# MIMXRT685S_cm33 register map
Vendor: nxp.com; File version: 1.0
CPU: CM33 r2p0, little endian, MPU, FPU, VTOR, 3 interrupt priority bits
Registers are 32-bit, read-write, reset 0x0 unless marked. A register's access mark holds for its fields unless they carry their own. Offsets are from the block's base; [hi:lo] are bit positions; {n}, {i} and the like mark numbered series.

## USBHSD — LPC54S60x/LPC5460x USB1 High-speed Device Controller
Base 0x40144000
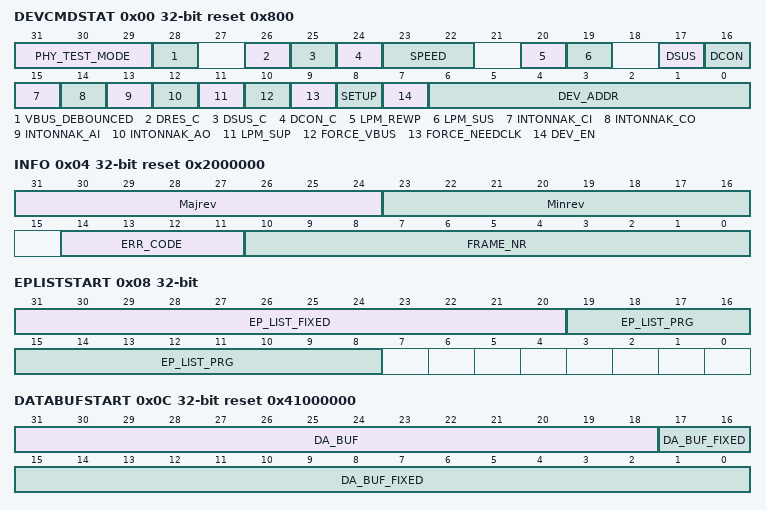
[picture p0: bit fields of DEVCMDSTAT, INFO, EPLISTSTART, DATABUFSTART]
0x00 DEVCMDSTAT reset 0x800 — USB Device Command/Status register
  [31:29] PHY_TEST_MODE — This field is written by firmware to put the PHY into a test mode as defined by the USB2.0 specification.
  [28] VBUS_DEBOUNCED ro — This bit indicates if VBUS is detected or not.
  [26] DRES_C — Device status - reset change.
  [25] DSUS_C — Device status - suspend change.
  [24] DCON_C — Device status - connect change.
  [23:22] SPEED ro — This field indicates the speed at which the device operates: 00b: reserved 01b: full-speed 10b: high-speed 11b: super-speed (reserved for future use).
  [20] LPM_REWP ro — LPM Remote Wake-up Enabled by USB host.
  [19] LPM_SUS — Device status - LPM Suspend.
  [17] DSUS — Device status - suspend.
  [16] DCON — Device status - connect.
  [15] INTONNAK_CI — Interrupt on NAK for control IN EP:.
  [14] INTONNAK_CO — Interrupt on NAK for control OUT EP:.
  [13] INTONNAK_AI — Interrupt on NAK for interrupt and bulk IN EP:.
  [12] INTONNAK_AO — Interrupt on NAK for interrupt and bulk OUT EP:.
  [11] LPM_SUP — LPM Supported:.
  [10] FORCE_VBUS — If this bit is set to 1, the VBUS voltage indicators from the PHY are overruled.
  [9] FORCE_NEEDCLK — Forces the NEEDCLK output to always be on:.
  [8] SETUP — SETUP token received.
  [7] DEV_EN — USB device enable.
  [6:0] DEV_ADDR — USB device address.
0x04 INFO ro reset 0x2000000 — USB Info register
  [31:24] Majrev — Major revision.
  [23:16] Minrev — Minor revision.
  [14:11] ERR_CODE — The error code which last occurred:.
  [10:0] FRAME_NR — Frame number.
0x08 EPLISTSTART — USB EP Command/Status List start address
  [31:20] EP_LIST_FIXED ro — Fixed portion of USB EP Command/Status List address.
  [19:8] EP_LIST_PRG — Programmable portion of the USB EP Command/Status List address.
0x0C DATABUFSTART reset 0x41000000 — USB Data buffer start address
  [31:18] DA_BUF — Programmable portion of the data buffer start address.
  [17:0] DA_BUF_FIXED ro — The fixed portion of the data buffer start address.
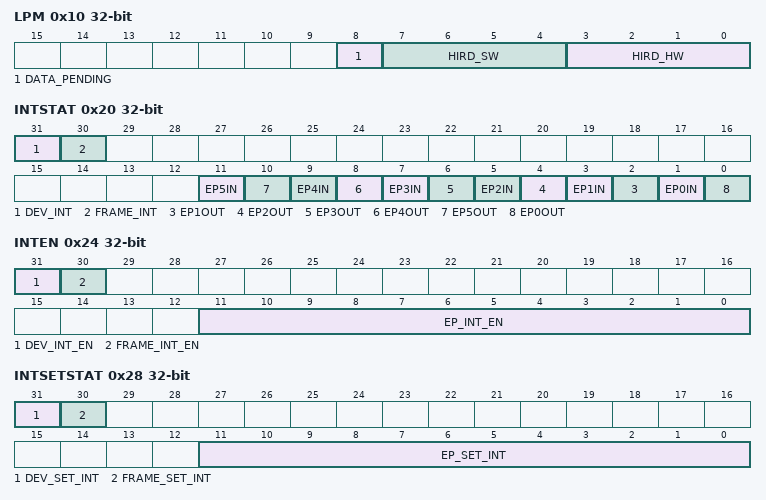
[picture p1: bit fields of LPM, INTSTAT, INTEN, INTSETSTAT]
0x10 LPM — USB Link Power Management register
  [8] DATA_PENDING — As long as this bit is set to one and LPM supported bit is set to one, HW will return a NYET handshake on every LPM token it receives.
  [7:4] HIRD_SW — Host Initiated Resume Duration - SW.
  [3:0] HIRD_HW ro — Host Initiated Resume Duration - HW.
0x14 EPSKIP — USB Endpoint skip
  [11:0] SKIP — Endpoint skip: Writing 1 to one of these bits, will indicate to HW that it must deactivate the buffer assigned to this endpoint and return control back to software.
0x18 EPINUSE — USB Endpoint Buffer in use
  [11:2] BUF — Buffer in use: This register has one bit per physical endpoint.
0x1C EPBUFCFG — USB Endpoint Buffer Configuration register
  [11:2] BUF_SB — Buffer usage: This register has one bit per physical endpoint.
0x20 INTSTAT — USB interrupt status register
  [31] DEV_INT — Device status interrupt.
  [30] FRAME_INT — Frame interrupt.
  [2n+1] EP{n}IN (n=1..5) — Interrupt status register bit for the EP{n} IN direction.
  [2n] EP{n}OUT (n=1..5) — Interrupt status register bit for the EP{n} OUT direction.
  [1] EP0IN — Interrupt status register bit for the Control EP0 IN direction.
  [0] EP0OUT — Interrupt status register bit for the Control EP0 OUT direction.
0x24 INTEN — USB interrupt enable register
  [31] DEV_INT_EN — If this bit is set and the corresponding USB interrupt status bit is set, a HW interrupt is generated on the interrupt line.
  [30] FRAME_INT_EN — If this bit is set and the corresponding USB interrupt status bit is set, a HW interrupt is generated on the interrupt line.
  [11:0] EP_INT_EN — If this bit is set and the corresponding USB interrupt status bit is set, a HW interrupt is generated on the interrupt line.
0x28 INTSETSTAT — USB set interrupt status register
  [31] DEV_SET_INT — If software writes a one to one of these bits, the corresponding USB interrupt status bit is set.
  [30] FRAME_SET_INT — If software writes a one to one of these bits, the corresponding USB interrupt status bit is set.
  [11:0] EP_SET_INT — If software writes a one to one of these bits, the corresponding USB interrupt status bit is set.
0x34 EPTOGGLE ro — USB Endpoint toggle register
  [29:0] TOGGLE — Endpoint data toggle: This field indicates the current value of the data toggle for the corresponding endpoint.
